# EFR32FG23B010F512IM48 register map
Vendor: Silicon Labs; Series: EFR32; File version: C
CPU: CM33 r0p4, little endian, MPU, FPU, DSP, VTOR, 4 interrupt priority bits, 8 SAU regions
Registers are 32-bit, read-write, reset 0x0 unless marked. A register's access mark holds for its fields unless they carry their own. Offsets are from the block's base; [hi:lo] are bit positions; {n}, {i} and the like mark numbered series.

## LCD_NS — LCD_NS Registers
Base 0x500AC000
Same registers: LCD_S 0x400AC000
0x00 IPVERSION ro reset 0x1
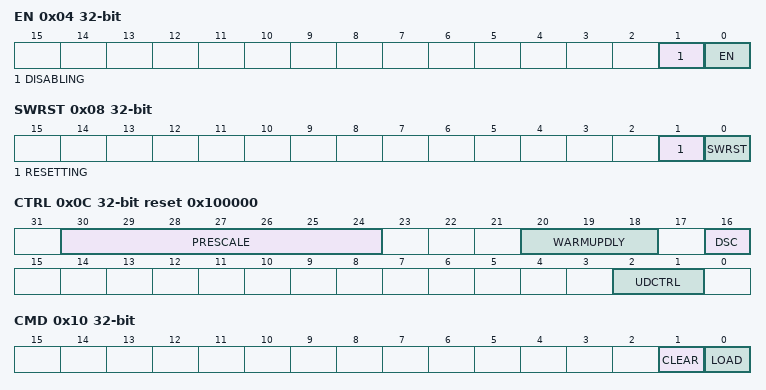
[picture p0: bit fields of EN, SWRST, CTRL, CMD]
0x04 EN
  [1] DISABLING ro — Disablement busy status
  [0] EN — Enable
    0=DISABLE; 1=ENABLE
0x08 SWRST
  [1] RESETTING ro — Software reset busy status
  [0] SWRST wo — Software reset command
0x0C CTRL reset 0x100000
  [30:24] PRESCALE — Presclae
  [20:18] WARMUPDLY — Warmup Delay
    0=WARMUP1 (1mswarm up); 1=WARMUP31 (31ms warm up); 2=WARMUP63 (62ms warm up); 3=WARMUP125 (125ms warm up); 4=WARMUP250 (250ms warm up); 5=WARMUP500 (500ms warm up); 6=WARMUP1000 (1000ms warm up); 7=WARMUP2000 (2000ms warm up)
  [16] DSC — Direct Segment Control
    0=DISABLE (DSC disable); 1=ENABLE (DSC enable)
  [2:1] UDCTRL — Update Data Control
    0=REGULAR (The data transfer is controlled by SW. Transfer is performed as soon as possible on the next CTRL.PRESCALE clock. This is primarily available for debug only since only some of the new SEGMENT data may be ready by the time of the UPDATE. This should not be used with interrupts since partially updating SEGMENT data may have indeterminant results.); 1=FRAMESTART (Data is loaded continuously at every frame start); 2=FCEVENT (The data transfer is done at the next Frame Counter event); 3=DISPLAYEVENT (The data transfer is done at the next Display Counter event)
0x10 CMD wo
  [1] CLEAR — Clear command
  [0] LOAD — Load command
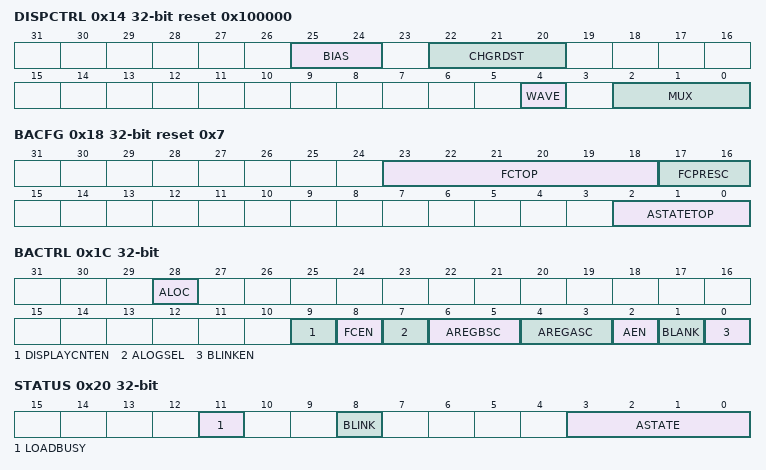
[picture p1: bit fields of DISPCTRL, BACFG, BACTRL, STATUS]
0x14 DISPCTRL reset 0x100000
  [25:24] BIAS — Bias Configuration
    0=STATIC; 1=ONEHALF (1/2 Bias); 2=ONETHIRD (1/3 Bias); 3=ONEFOURTH (1/4 Bias)
  [22:20] CHGRDST — Charge Redistribution Cycles
    0=DISABLE (Disable charge redistribution.); 1=ONE (Use 1 prescaled low frequency clock cycle for charge redistribution.); 2=TWO (Use 2 prescaled low frequency clock cycles for charge redistribution.); 3=THREE (Use 3 prescaled low frequency clock cycles for charge redistribution.); 4=FOUR (Use 4 prescaled low frequency clock cycles for charge redistribution.)
  [4] WAVE — Waveform Selection
    0=TYPEB (Type B waveform); 1=TYPEA (Type A waveform)
  [2:0] MUX — Mux Configuration
    0=STATIC; 1=DUPLEX; 2=TRIPLEX; 3=QUADRUPLEX
0x18 BACFG reset 0x7
  [23:18] FCTOP — Frame Counter Top
  [17:16] FCPRESC — Frame Counter Prescaler
    0=DIV1 (every frame clock); 1=DIV2 (every 2nd frame clock); 2=DIV4 (every 4th frame clock); 3=DIV8 (every 8th frame clock)
  [2:0] ASTATETOP — ASTATE top cnt
0x1C BACTRL
  [28] ALOC — Animation Location
    0=SEG0TO7 (Animation appears on segments 0 to 7); 1=SEG8TO15 (Animation appears on segments 8 to 15)
  [9] DISPLAYCNTEN — Display Counter Enable
    0=DISABLE (Disable the display counter); 1=ENABLE (Enable the display counter)
  [8] FCEN — Frame Counter Enable
  [7] ALOGSEL — Animate Logic Function Select
    0=AND (AREGA and AREGB AND'ed); 1=OR (AREGA and AREGB OR'ed)
  [6:5] AREGBSC — Animate Register B Shift Control
    0=NOSHIFT (No Shift operation on Animation Register B); 1=SHIFTLEFT (Animation Register B is shifted left); 2=SHIFTRIGHT (Animation Register B is shifted right)
  [4:3] AREGASC — Animate Register A Shift Control
    0=NOSHIFT (No Shift operation on Animation Register A); 1=SHIFTLEFT (Animation Register A is shifted left); 2=SHIFTRIGHT (Animation Register A is shifted right)
  [2] AEN — Animation Enable
  [1] BLANK — Blank Display
    0=DISABLE (Display is not "blanked"); 1=ENABLE (Display is "blanked")
  [0] BLINKEN — Blink Enable
0x20 STATUS ro
  [11] LOADBUSY — Load Synchronization is busy
  [8] BLINK — Blink State
  [3:0] ASTATE — Current Animation State
0x24 AREGA
  [7:0] AREGA — Animation Register A Data
0x28 AREGB
  [7:0] AREGB — Animation Register B Data
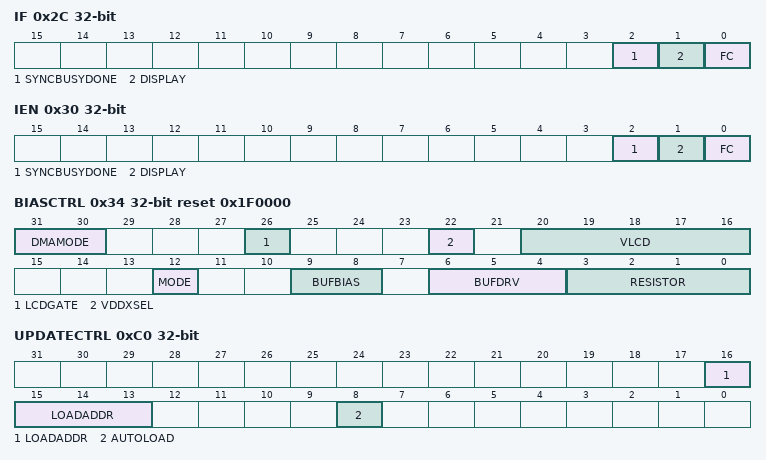
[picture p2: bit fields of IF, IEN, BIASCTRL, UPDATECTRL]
0x2C IF
  [2] SYNCBUSYDONE — Synchronization is Done
  [1] DISPLAY — Display Update Event
  [0] FC — Frame Counter
0x30 IEN
  [2] SYNCBUSYDONE
  [1] DISPLAY — Display Update Event
  [0] FC — Frame Counter
0x34 BIASCTRL reset 0x1F0000
  [31:30] DMAMODE
    0=DMADISABLE (No DMA requests are generated); 1=DMAFC (DMA request on frame counter event. This will also start a DMA transfer during EM23.); 2=DMADISPLAY (DMA request on display counter event. This will also start a DMA transfer during EM23.)
  [26] LCDGATE
    0=UNGATE (LCD BIAS voltages driven onto pins.); 1=GATE (LCD BIAS MUX tristated at the pins.)
  [22] VDDXSEL — VDDX select
    0=DVDD (Connect charge pump to digital DVDD supply); 1=AVDD (Connect charge pump to analog AVDD supply)
  [20:16] VLCD — VLCD voltage level
  [12] MODE — Mode Setting
    0=STEPDOWN (Use step down control with VLCD less than VDDX. Use VLCD[4:0] to control VLCD level, and use SPEED to adjust VLCD drive strength.); 1=CHARGEPUMP (Use the charge pump to pump VLCD above VDDX.)
  [9:8] BUFBIAS — Buffer Bias Setting
  [6:4] BUFDRV — Buffer Drive Strength
  [3:0] RESISTOR — Resistor strength
0x38 DISPCTRLX
  [9:0] DISPLAYDIV — Display Divider
{0x40+8i} SEGD{i} (i=0..3)
  [19:0] SEGD{i} — COM{i} Segment Data Low
0xC0 UPDATECTRL
  [16:13] LOADADDR — Load Address
    0=BACTRLWR (Starts synchronizing registers from CLK_BUS to CLK_PER after a write to BACTRL. Use with UPDATECTRL.AUTOLOAD); 1=AREGAWR (Starts synchronizing registers from CLK_BUS to CLK_PER after a write to AREGA. Use with UPDATECTRL.AUTOLOAD); 2=AREGBWR (Starts synchronizing registers from CLK_BUS to CLK_PER after a write to AREGB. Use with UPDATECTRL.AUTOLOAD); {v}=SEGD{v-3}WR (Starts synchronizing registers from CLK_BUS to CLK_PER after a write to SEGD{v-3}. Use with UPDATECTRL.AUTOLOAD) (v=3..6)
  [8] AUTOLOAD
    0=MANUAL (CLK_BUS register to CLK_PER register loads must be done manually with a write to CMD.LOAD.); 1=AUTO (CLK_BUS register to CLK_PER register loads will be started automatically after a write to the register in UPDATECTRL.LOADADDR is detected.)
0xF0 FRAMERATE
  [8:0] FRDIV — Frame Rate Divider
